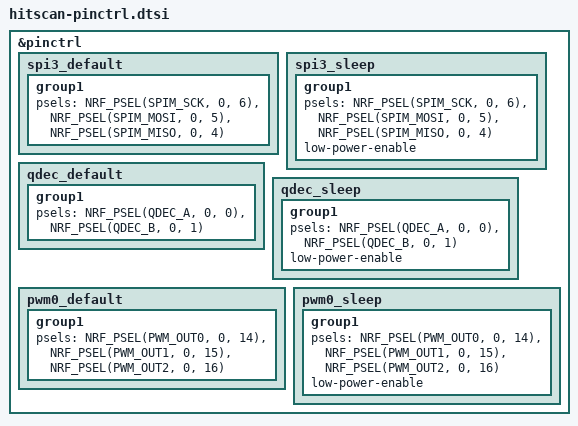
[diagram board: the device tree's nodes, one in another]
/*
 * Copyright (c) 2022 Nordic Semiconductor ASA
 *
 * SPDX-License-Identifier: LicenseRef-Nordic-5-Clause
 */

&pinctrl {
	spi3_default: spi3_default {
		group1 {
			psels = <NRF_PSEL(SPIM_SCK, 0, 6)>,
				<NRF_PSEL(SPIM_MOSI, 0, 5)>,
				<NRF_PSEL(SPIM_MISO, 0, 4)>;
		};
	};

	spi3_sleep: spi3_sleep {
		group1 {
			psels = <NRF_PSEL(SPIM_SCK, 0, 6)>,
				<NRF_PSEL(SPIM_MOSI, 0, 5)>,
				<NRF_PSEL(SPIM_MISO, 0, 4)>;
			low-power-enable;
		};
	};

	qdec_default: qdec_default {
		group1 {
			psels = <NRF_PSEL(QDEC_A, 0, 0)>,
				<NRF_PSEL(QDEC_B, 0, 1)>;
		};
	};

	qdec_sleep: qdec_sleep {
		group1 {
			psels = <NRF_PSEL(QDEC_A, 0, 0)>,
				<NRF_PSEL(QDEC_B, 0, 1)>;
			low-power-enable;
		};
	};

	pwm0_default: pwm0_default {
		group1 {
			psels = <NRF_PSEL(PWM_OUT0, 0, 14)>,
				<NRF_PSEL(PWM_OUT1, 0, 15)>,
				<NRF_PSEL(PWM_OUT2, 0, 16)>;
		};
	};

	pwm0_sleep: pwm0_sleep {
		group1 {
			psels = <NRF_PSEL(PWM_OUT0, 0, 14)>,
				<NRF_PSEL(PWM_OUT1, 0, 15)>,
				<NRF_PSEL(PWM_OUT2, 0, 16)>;
			low-power-enable;
		};
	};
};
